# DA1470x register map
Vendor: Dialog; Series: DA1470x; File version: 1.2
CPU: CM33 r0p2, little endian, MPU, FPU, DSP, VTOR, 4 interrupt priority bits
Registers are 32-bit, read-write, reset 0x0 unless marked. A register's access mark holds for its fields unless they carry their own. Offsets are from the block's base; [hi:lo] are bit positions.

## EMMC (part 1 of 3) — EMMC registers
Base 0x30058000
0x00 EMMC_SDMASA_R_REG (reset mask 0x7FFFFFFF) — This register is used to configure a 32-bit Block Count or an SDMA System Address based on the Host Version 4 Enable bit in the
  [31:0] BLOCKCNT_SDMASA — 32-bit Block Count (SDMA System Address). - SDMA System Address (Host Version 4 Enable = 0): This register contains the system memory address for an SDMA transfer in the 32-bit addressing mode. When the Host Controller stops an SDMA transfer, this register points to the system address of the next contiguous data position. It can be accessed only if no transaction is executing. Reading this register during data transfers may return an invalid value. - 32-bit Block Count (Host Version 4 Enable = 1): From the Host Controller Version 4.10 specification, this register is redefined as 32-bit Block Count. The Host Controller decrements the block count of this register for every block transfer and the data transfer stops when the count reaches zero. This register must be accessed when no transaction is executing. Reading this register during data transfers may return invalid value. Following are the values for BLOCKCNT_SDMASA: - 0xFFFF_FFFF: 4G - 1 Block - ... - 0x0000_0002: 2 Blocks - 0x0000_0001: 1 Block - 0x0000_0000: Stop Count Note: - For Host Version 4 Enable = 0, the Host driver does not program the system address in this register while operating in ADMA mode. The system address must be programmed in the ADMA System Address register. - For Host Version 4 Enable = 0, the Host driver programs a non-zero 32-bit block count value in this register when Auto CMD23 is enabled for non-DMA and ADMA modes. Auto CMD23 cannot be used with SDMA. - This register must be programmed with a non-zero value for data transfer if the 32-bit Block count register is used instead of the 16-bit Block count register.
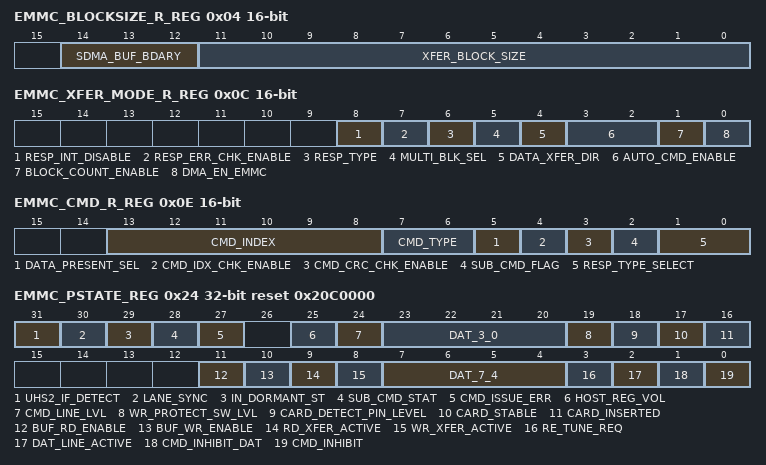
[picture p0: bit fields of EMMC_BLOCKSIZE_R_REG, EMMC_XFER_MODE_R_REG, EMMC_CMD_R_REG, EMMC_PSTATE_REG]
0x04 EMMC_BLOCKSIZE_R_REG 16-bit — This register is used to configure an SDMA buffer boundary and the number of bytes in a data block. This register is applicable
  [14:12] SDMA_BUF_BDARY — SDMA Buffer Boundary. These bits specify the size of contiguous buffer in system memory. The SDMA transfer waits at every boundary specified by these fields and the Host Controller generates the DMA interrupt to request the Host Driver to update the SDMA System Address register. Values: 0x0 (BYTES_4K): 4K bytes SDMA Buffer Boundary 0x1 (BYTES_8K): 8K bytes SDMA Buffer Boundary 0x2 (BYTES_16K): 16K bytes SDMA Buffer Boundary 0x3 (BYTES_32K): 32K bytes SDMA Buffer Boundary 0x4 (BYTES_64K): 64K bytes SDMA Buffer Boundary 0x5 (BYTES_128K): 128K bytes SDMA Buffer Boundary 0x6 (BYTES_256K): 256K bytes SDMA Buffer Boundary 0x7 (BYTES_512K): 512K bytes SDMA Buffer Boundary
  [11:0] XFER_BLOCK_SIZE — Transfer Block Size. These bits specify the block size of data transfers. In case of memory, it is set to 512 bytes. It can be accessed only if no transaction is executing. Read operations during transfers may return an invalid value, and write operations are ignored. Following are the values for XFER_BLOCK_SIZE: - 0x1: 1 byte - 0x2: 2 bytes - 0x3: 3 bytes - ...... - 0x1FF: 511 byte - 0x200: 512 bytes - ...... - 0x800: 2048 bytes Note: This register must be programmed with a non-zero value for data transfer.
0x06 EMMC_BLOCKCOUNT_R_REG 16-bit — This register is used to configure the number of data blocks. This register is applicable for both SD and eMMC modes.
  [15:0] BLOCK_CNT — 16-bit Block Count. - If the Host Version 4 Enable bit is set 0 or the 16-bit Block Count register is set to non-zero, the 16-bit Block Count register is selected. - If the Host Version 4 Enable bit is set 1 and the 16-bit Block Count register is set to zero, the 32-bit Block Count register is selected. Following are the values for BLOCK_CNT: - 0x0: Stop Count - 0x1: 1 Block - 0x2: 2 Blocks - ... - ... - 0xFFFF: 65535 Blocks Note: For Host Version 4 Enable = 0, this register must be set to 0000h before programming the 32-bit block count register when Auto CMD23 is enabled for non-DMA and ADMA modes.
0x08 EMMC_ARGUMENT_R_REG (reset mask 0x7FFFFFFF) — This register is used to configure the SD/eMMC command argument.
  [31:0] ARGUMENT — Command Argument. These bits specify the SD/eMMC command argument that is specified in bits 39-8 of the Command format.
0x0C EMMC_XFER_MODE_R_REG 16-bit — This register is used to control the operation of data transfers for an SD/eMMC mode. The Host driver sets this register before
  [8] RESP_INT_DISABLE — Response Interrupt Disable. The Host Controller supports response check function to avoid overhead of response error check by the Host driver. Response types of only R1 and R5 can be checked by the Controller. If Host Driver checks the response error, set this bit to 0 and wait for Command Complete Interrupt and then check the response register. If the Host Controller checks the response error, set this bit to 1 and set the Response Error Check Enable bit to 1. The Command Complete Interrupt is disabled by this bit regardless of the Command Complete Signal Enable. Note: During tuning (when the Execute Tuning bit in the Host Control2 register is set), the Command Complete Interrupt is not generated irrespective of the Response Interrupt Disable setting. Values: 0x0 (ENABLED): Response Interrupt is enabled 0x1 (DISABLED): Response Interrupt is disabled
  [7] RESP_ERR_CHK_ENABLE — Response Error Check Enable. The Host Controller supports response check function to avoid overhead of response error check by Host driver. Response types of only R1 and R5 can be checked by the Controller. If the Host Controller checks the response error, set this bit to 1 and set Response Interrupt Disable to 1. If an error is detected, the Response Error interrupt is generated in the Error Interrupt Status register. Note: - Response error check must not be enabled for any response type other than R1 and R5. - Response check must not be enabled for the tuning command. Values: 0x0 (DISABLED): Response Error Check is disabled 0x1 (ENABLED): Response Error Check is enabled
  [6] RESP_TYPE — Response Type R1/R5. This bit selects either R1 or R5 as a response type when the Response Error Check is selected. Error statuses checked in R1: - OUT_OF_RANGE - ADDRESS_ERROR - BLOCK_LEN_ERROR - WP_VIOLATION - CARD_IS_LOCKED - COM_CRC_ERROR - CARD_ECC_FAILED - CC_ERROR - ERROR Response Flags checked in R5: - COM_CRC_ERROR - ERROR - FUNCTION_NUMBER - OUT_OF_RANGE Values: 0x0 (RESP_R1): R1 (Memory) 0x1 (RESP_R5): R5 (SDIO)
  [5] MULTI_BLK_SEL — Multi/Single Block Select. This bit is set when issuing multiple-block transfer commands using the DAT line. If this bit is set to 0, it is not necessary to set the Block Count register. Values: 0x0 (SINGLE): Single Block 0x1 (MULTI): Multiple Block
  [4] DATA_XFER_DIR — Data Transfer Direction Select. This bit defines the direction of DAT line data transfers. This bit is set to 1 by the Host Driver to transfer data from the SD/eMMC card to the Host Controller and it is set to 0 for all other commands. Values: 0x1 (READ): Read (Card to Host) 0x0 (WRITE): Write (Host to Card)
  [3:2] AUTO_CMD_ENABLE — Auto Command Enable. This field determines use of Auto Command functions. Note: In SDIO, this field must be set as 00b (Auto Command Disabled). Values: 0x0 (AUTO_CMD_DISABLED): Auto Command Disabled 0x1 (AUTO_CMD12_ENABLED): Auto CMD12 Enable 0x2 (AUTO_CMD23_ENABLED): Auto CMD23 Enable 0x3 (AUTO_CMD_AUTO_SEL): Auto CMD Auto Select
  [1] BLOCK_COUNT_ENABLE — Block Count Enable. This bit is used to enable the Block Count register, which is relevant for multiple block transfers. If this bit is set to 0, the Block Count register is disabled, which is useful in executing an infinite transfer. The Host Driver must set this bit to 0 when ADMA is used. Values: 0x1 (ENABLED): Enable 0x0 (DISABLED): Disable
  [0] DMA_EN_EMMC — DMA Enable. This bit enables the DMA functionality. If this bit is set to 1, a DMA operation begins when the Host Driver writes to the Command register. You can select one of the DMA modes by using DMA Select in the Host Control 1 register. Values: 0x1 (ENABLED): DMA Data transfer 0x0 (DISABLED): No data transfer or Non-DMA data transfer
0x0E EMMC_CMD_R_REG 16-bit — This register is used to provide the information related to a command and a response packet. This register is applicable for an
  [13:8] CMD_INDEX — Command Index. These bits are set to the command number that is specified in bits 45-40 of the Command Format.
  [7:6] CMD_TYPE — Command Type. These bits indicate the command type. Note: While issuing Abort CMD using CMD12/CMD52 or reset CMD using CMD0/CMD52, CMD_TYPE field shall be set to 0x3. Values: 0x3 (ABORT_CMD): Abort 0x2 (RESUME_CMD): Resume 0x1 (SUSPEND_CMD): Suspend 0x0 (NORMAL_CMD): Normal
  [5] DATA_PRESENT_SEL — Data Present Select. This bit is set to 1 to indicate that data is present and that the data is transferred using the DAT line. This bit is set to 0 in the following instances: - Command using the CMD line - Command with no data transfer but using busy signal on the DAT[0] line - Resume Command Values: 0x0 (NO_DATA): No Data Present 0x1 (DATA): Data Present
  [4] CMD_IDX_CHK_ENABLE — Command Index Check Enable. This bit enables the Host Controller to check the index field in the response to verify if it has the same value as the command index. If the value is not the same, it is reported as a Command Index error. Note: - Index Check enable must be set to 0 for the command with no response, R2 response, R3 response and R4 response. - For the tuning command, this bit must always be set to enable the index check. Values: 0x0 (DISABLED): Disable 0x1 (ENABLED): Enable
  [3] CMD_CRC_CHK_ENABLE — Command CRC Check Enable. This bit enables the Host Controller to check the CRC field in the response. If an error is detected, it is reported as a Command CRC error. Note: - CRC Check enable must be set to 0 for the command with no response, R3 response, and R4 response. - For the tuning command, this bit must always be set to 1 to enable the CRC check. Values: 0x0 (DISABLED): Disable 0x1 (ENABLED): Enable
  [2] SUB_CMD_FLAG — Sub Command Flag. This bit distinguishes between a main command and a sub command. Values: 0x0 (MAIN): Main Command 0x1 (SUB): Sub Command
  [1:0] RESP_TYPE_SELECT — Response Type Select. This bit indicates the type of response expected from the card. Values: 0x0 (NO_RESP): No Response 0x1 (RESP_LEN_136): Response Length 136 0x2 (RESP_LEN_48): Response Length 48 0x3 (RESP_LEN_48B): Response Length 48; Check Busy after response
0x10 EMMC_RESP01_R_REG (reset mask 0x7FFFFFFF) — This register stores 39-08 bits of the Response Field for an SD/eMMC mode. The response for an SD/eMMC command can be a maximu
  [31:0] RESP01 ro — Command Response. These bits reflect 39-8 bits of SD/eMMC Response Field. Note: For Auto CMD, the 32-bit response (bits 39-8 of the Response Field) is updated in the RESP67_R register.
0x14 EMMC_RESP23_R_REG (reset mask 0x7FFFFFFF) — This register stores 71-40 bits of the Response Field for an SD/eMMC mode. This register is used to store the response from the
  [31:0] RESP23 ro — Command Response. These bits reflect 71-40 bits of the SD/eMMC Response Field.
0x18 EMMC_RESP45_R_REG (reset mask 0x7FFFFFFF) — This register stores 103-72 bits of the Response Field for an SD/eMMC mode. The response for SD/eMMC command can be a maximum
  [31:0] RESP45 ro — Command Response. These bits reflect 103-72 bits of the Response Field.
0x1C EMMC_RESP67_R_REG (reset mask 0x7FFFFFFF) — This register stores 135-104 bits of the Response Field for an SD/eMMC mode. The SD/eMMC response can be a maximum of 128 bi
  [31:0] RESP67 ro — Command Response. These bits reflect bits 135-104 of SD/EMMC Response Field. Note: For Auto CMD, this register also reflects the 32-bit response (bits 39-8 of the Response Field).
0x20 EMMC_BUF_DATA_R_REG (reset mask 0x7FFFFFFF) — This register is used to access the packet buffer. This register is applicable for an SD/eMMC/UHS-II mode.
  [31:0] BUF_DATA — Buffer Data. These bits enable access to the Host Controller packet buffer.
0x24 EMMC_PSTATE_REG reset 0x20C0000 (reset mask 0x7FFFFFFF) — This register indicates the present status of the Host Controller. This register is applicable for an SD/eMMC/UHS-II mode.
  [31] UHS2_IF_DETECT ro — UHS-II Interface Detection. For SD/eMMC mode, this bit always returns 0. Values: 0x0 (FALSE): UHS-II interface is not detected 0x1 (TRUE): UHS-II interface is detected
  [30] LANE_SYNC ro — Lane Synchronization. For SD/eMMC mode, this bit always returns 0. Values: 0x0 (FALSE): UHS-II PHY is not initialized 0x1 (TRUE): UHS-II PHY is initialized
  [29] IN_DORMANT_ST ro — In Dormant Status For SD/eMMC mode, this bit always returns 0. Values: 0x0 (FALSE): Not in DORMANT state 0x1 (TRUE): In DORMANT state
  [28] SUB_CMD_STAT ro — Sub Command Status. This bit is used to distinguish between a main command and a sub command status. Values: 0x0 (FALSE): Main Command Status 0x1 (TRUE): Sub Command Status
  [27] CMD_ISSUE_ERR ro — Command Not Issued by Error. This bit is set if a command cannot be issued after setting the command register due to an error except the Auto CMD12 error. Values: 0x0 (FALSE): No error for issuing a command 0x1 (TRUE): Command cannot be issued
  [25] HOST_REG_VOL ro — Host Regulator Voltage Stable. This bit is used to check whether the host regulator voltage is stable for switching the voltage of UHS-I mode. This bit reflects the synchronized value of the host_reg_vol_stable signal. Values: Description 0x0 (FALSE): Host Regulator Voltage is not stable 0x1 (TRUE): Host Regulator Voltage is stable
  [24] CMD_LINE_LVL ro — Command-Line Signal Level. This bit is used to check the CMD line level to recover from errors and for debugging. These bits reflect the value of the sd_cmd_in signal.
  [23:20] DAT_3_0 ro — DAT[3:0] Line Signal Level. This bit is used to check the DAT line level to recover from errors and for debugging. These bits reflect the value of the sd_dat_in (lower nibble) signal.
  [19] WR_PROTECT_SW_LVL ro — Write Protect Switch Pin Level. This bit is supported only for memory and combo cards. This bit reflects the synchronized value of the card_write_prot signal. Values: 0x0 (FALSE): Write protected 0x1 (TRUE): Write enabled
  [18] CARD_DETECT_PIN_LEVEL ro — Card Detect Pin Level. This bit reflects the inverse synchronized value of the card_detect_n signal. Values: 0x0 (FALSE): No card present 0x1 (TRUE): Card Present
  [17] CARD_STABLE ro — Card Stable. This bit indicates the stability of the Card Detect Pin Level. A card is not detected if this bit is set to 1 and the value of the CARD_INSERTED bit is 0. Values: 0x0 (FALSE): Reset or Debouncing 0x1 (TRUE): No Card or Inserted
  [16] CARD_INSERTED ro — Card Inserted. This bit indicates whether a card has been inserted. The Host Controller debounces this signal so that Host Driver need not wait for it to stabilize. Values: 0x0 (FALSE): Reset, Debouncing, or No card 0x1 (TRUE): Card Inserted
  [11] BUF_RD_ENABLE ro — Buffer Read Enable. This bit is used for non-DMA transfers. This bit is set if valid data exists in the Host buffer. Values: 0x0 (DISABLED): Read disable 0x1 (ENABLED): Read enable
  [10] BUF_WR_ENABLE ro — Buffer Write Enable. This bit is used for non-DMA transfers. This bit is set if space is available for writing data. Values: 0x0 (DISABLED): Write disable 0x1 (ENABLED): Write enable
  [9] RD_XFER_ACTIVE ro — Read Transfer Active. This bit indicates whether a read transfer is active for SD/eMMC mode. Values: 0x0 (INACTIVE): No valid data 0x1 (ACTIVE): Transferring data
  [8] WR_XFER_ACTIVE ro — Write Transfer Active. This status indicates whether a write transfer is active for SD/eMMC mode. Values: 0x0 (INACTIVE): No valid data 0x1 (ACTIVE): Transferring data
  [7:4] DAT_7_4 ro — DAT[7:4] Line Signal Level. This bit is used to check the DAT line level to recover from errors and for debugging. These bits reflect the value of the sd_dat_in (upper nibble) signal.
  [3] RE_TUNE_REQ ro — Re-Tuning Request. DWC_mshc does not generate retuning request. The software must maintain the Retuning timer.
  [2] DAT_LINE_ACTIVE ro — DAT Line Active (SD/eMMC Mode only). This bit indicates whether one of the DAT lines on the SD/eMMC bus is in use. In the case of read transactions, this bit indicates whether a read transfer is executing on the SD/eMMC bus. In the case of write transactions, this bit indicates whether a write transfer is executing on the SD/eMMC bus. For a command with busy, this status indicates whether the command executing busy is executing on an SD or eMMC bus. Values: 0x0 (INACTIVE): DAT Line Inactive 0x1 (ACTIVE): DAT Line Active
  [1] CMD_INHIBIT_DAT ro — Command Inhibit (DAT). This bit is applicable for SD/eMMC mode and is generated if either DAT line active or Read transfer active is set to 1. If this bit is set to 0, it indicates that the Host Controller can issue subsequent SD/eMMC commands. Values: 0x0 (READY): Can issue command which used DAT line 0x1 (NOT_READY): Cannot issue command which used DAT line
  [0] CMD_INHIBIT ro — Command Inhibit (CMD). This bit indicates the following : - SD/eMMC mode: If this bit is set to 0, it indicates that the CMD line is not in use and the Host controller can issue an SD/eMMC command using the CMD line. This bit is set when the command register is written. This bit is cleared when the command response is received. This bit is not cleared by the response of auto CMD12/23 but cleared by the response of read/write command. Values: 0x0 (READY): Host Controller is ready to issue a command 0x1 (NOT_READY): Host Controller is not ready to issue a command
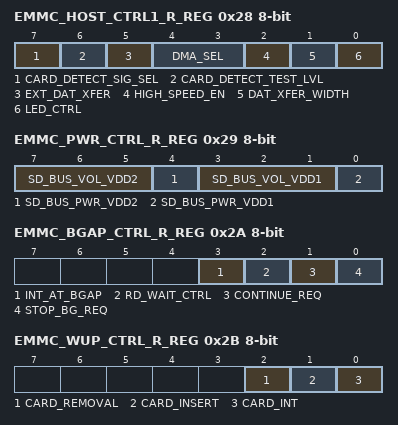
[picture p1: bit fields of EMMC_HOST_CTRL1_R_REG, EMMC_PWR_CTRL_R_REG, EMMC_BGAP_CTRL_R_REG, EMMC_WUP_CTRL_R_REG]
0x28 EMMC_HOST_CTRL1_R_REG 8-bit — This register is used to control the operation of the Host Controller. This register is applicable for an SD/eMMC/UHS-II mode.
  [7] CARD_DETECT_SIG_SEL — Card Detect Signal Selection. This bit selects a source for card detection. When the source for the card detection is switched, the interrupt must be disabled during the switching period. Values: 0x1 (CARD_DT_TEST_LEVEL): Card Detect Test Level is selected (for test purpose) 0x0 (SDCD_PIN): SDCD# (card_detect_n signal) is selected (for normal use)
  [6] CARD_DETECT_TEST_LVL — Card Detect Test Level. This bit is enabled while the Card Detect Signal Selection is set to 1 and it indicates whether a card inserted or not. Values: 0x1 (CARD_INSERTED): Card Inserted 0x0 (No_CARD): No Card
  [5] EXT_DAT_XFER — Extended Data Transfer Width. This bit controls 8-bit bus width mode of embedded device. Values: 0x1 (EIGHT_BIT): 8-bit Bus Width 0x0 (DEFAULT): Bus Width is selected by the Data Transfer Width
  [4:3] DMA_SEL — DMA Select. This field is used to select the DMA type. When Host Version 4 Enable is 1 in Host Control 2 register: - 0x0 : SDMA is selected - 0x1 : Reserved - 0x2 : ADMA2 is selected - 0x3 : ADMA2 or ADMA3 is selected When Host Version 4 Enable is 0 in Host Control 2 register: - 0x0 : SDMA is selected - 0x1 : Reserved - 0x2 : 32-bit Address ADMA2 is selected - 0x3 : 64-bit Address ADMA2 is selected Values: 0x0 (SDMA): SDMA is selected 0x1 (RSVD_BIT): Reserved 0x2 (ADMA2): ADMA2 is selected 0x3 (ADMA2_3): ADMA2 or ADMA3 is selected
  [2] HIGH_SPEED_EN — High Speed Enable (SD/eMMC Mode only). In SD/eMMC mode, this bit is used to determine the selection of preset value for High Speed mode. Before setting this bit, the Host Driver checks the High Speed Support in the Capabilities register. Note: DWC_MSHC always outputs the sd_cmd_out and sd_dat_out lines at the rising edge of cclk_tx clock irrespective of this bit.Please refer the section Connecting the Clock IO interface in the Mobile Storage Host Controller user guide on clocking requirement for an SD/eMMC card. Values: 0x1 (HIGH_SPEED): High Speed mode 0x0 (NORMAL_SPEED): Normal Speed mode
  [1] DAT_XFER_WIDTH — Data Transfer Width. For SD/eMMC mode,this bit selects the data transfer width of the Host Controller. The Host Driver sets it to match the data width of the SD/eMMC card. Values: 0x1 (FOUR_BIT): 4-bit mode 0x0 (ONE_BIT): 1-bit mode
  [0] LED_CTRL — LED Control. This bit is used to caution the user not to remove the card while the SD card is being accessed. The value is reflected on the led_control signal. Values: 0x0 (OFF): LED off 0x1 (ON): LED on
0x29 EMMC_PWR_CTRL_R_REG 8-bit — This register is used to control the bus power for the Card. This register is applicable for an SD, eMMC, and UHS-II modes.
  [7:5] SD_BUS_VOL_VDD2 — SD Bus Voltage Select for VDD2. This is irrelevant for SD/eMMC card. Values: 0x7 (NOT_USED7): Not used 0x6 (NOT_USED6): Not used 0x5 (V_1_8): 1.8V 0x4 (V_1_2): Reserved for 1.2V 0x3 (RSVD3): Reserved 0x2 (RSVD2): Reserved 0x1 (RSVD1): Reserved 0x0 (NO_VDD2): VDD2 Not Supported
  [4] SD_BUS_PWR_VDD2 — SD Bus Power for VDD2. This is irrelevant for SD/eMMC card. Values: 0x0 (OFF): Power off 0x1 (ON): Power on
  [3:1] SD_BUS_VOL_VDD1 — SD Bus Voltage Select for VDD1/eMMC Bus Voltage Select for VDD. These bits enable the Host Driver to select the voltage level for an SD/eMMC card. Before setting this register, the Host Driver checks the Voltage Support bits in the Capabilities register. If an unsupported voltage is selected, the Host System does not supply the SD Bus voltage. The value set in this field is available on the DWC_mshc output signal (sd_vdd1_sel), which is used by the voltage switching circuitry. SD Bus Voltage Select options: - 0x7 : 3.3V(Typical) - 0x6 : 3.0V(Typical) - 0x5 : 1.8V(Typical) for Embedded - 0x4 : 0x0 - Reserved eMMC Bus Voltage Select options: - 0x7 : 3.3V(Typical) - 0x6 : 1.8V(Typical) - 0x5 : 1.2V(Typical) - 0x4 : 0x0 - Reserved Values: 0x7 (V_3_3): 3.3V (Typ.) 0x6 (V_3_0): 3.0V (Typ.) 0x5 (V_1_8): 1.8V (Typ.) for Embedded 0x4 (RSVD4): Reserved 0x3 (RSVD3): Reserved 0x2 (RSVD2): Reserved 0x1 (RSVD1): Reserved 0x0 (RSVD0): Reserved
  [0] SD_BUS_PWR_VDD1 — SD Bus Power for VDD1. This bit enables VDD1 power of the card. This setting is available on the sd_vdd1_on output of DWC_mshc so that it can be used to control the VDD1 power supply of the card. Before setting this bit, the SD Host Driver sets the SD Bus Voltage Select bit. If the Host Controller detects a No Card state, this bit is cleared. In SD mode, if this bit is cleared, the Host Controller stops the SD Clock by clearing the SD_CLK_IN bit in the CLK_CTRL_R register. Values: 0x0 (OFF): Power off 0x1 (ON): Power on
0x2A EMMC_BGAP_CTRL_R_REG 8-bit — This register is used by the host driver to control any operation related to Block Gap. This register is applicable for an SD/e
  [3] INT_AT_BGAP — Interrupt At Block Gap. This bit is valid only in the 4-bit mode of an SDIO card and is used to select a sample point in the interrupt cycle. Setting to 1 enables interrupt detection at the block gap for a multiple block transfer. Values: 0x0 (DISABLE): Disabled 0x1 (ENABLE): Enabled
  [2] RD_WAIT_CTRL — Read Wait Control. This bit is used to enable the read wait protocol to stop read data using DAT[2] line if the card supports read wait. Otherwise, the Host Controller has to stop the card clock to hold the read data. Values: 0x0 (DISABLE): Disable Read Wait Control 0x1 (ENABLE): Enable Read Wait Control
  [1] CONTINUE_REQ — Continue Request. This bit is used to restart the transaction, which was stopped using the Stop At Block Gap Request. The Host Controller automatically clears this bit when the transaction restarts. If stop at block gap request is set to 1, any write to this bit is ignored. Values: 0x0 (NO_AFFECT): No Affect 0x1 (RESTART): Restart
  [0] STOP_BG_REQ — Stop At Block Gap Request. This bit is used to stop executing read and write transactions at the next block gap for non-DMA, SDMA, and ADMA transfers. Values: 0x0 (XFER): Transfer 0x1 (STOP): Stop
0x2B EMMC_WUP_CTRL_R_REG 8-bit — This register is mandatory for the Host Controller, but the wakeup functionality depends on the Host Controller system hardware
  [2] CARD_REMOVAL — Wakeup Event Enable on SD Card Removal. This bit enables wakeup event through Card Removal assertion in the Normal Interrupt Status register. For the SDIO card, Wake Up Support (FN_WUS) in the Card Information Structure (CIS) register does not affect this bit. Values: 0x0 (DISABLED): Disable 0x1 (ENABLED): Enable
  [1] CARD_INSERT — Wakeup Event Enable on SD Card Insertion. This bit enables wakeup event through Card Insertion assertion in the Normal Interrupt Status register. FN_WUS (Wake Up Support) in CIS does not affect this bit. Values: 0x0 (DISABLED): Disable 0x1 (ENABLED): Enable
  [0] CARD_INT — Wakeup Event Enable on Card Interrupt. This bit enables wakeup event through a Card Interrupt assertion in the Normal Interrupt Status register. This bit can be set to 1 if FN_WUS (Wake Up Support) in CIS is set to 1. Values: 0x0 (DISABLED): Disable 0x1 (ENABLED): Enable
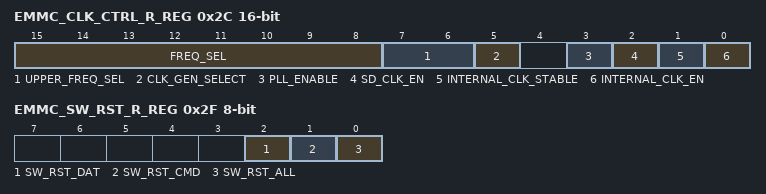
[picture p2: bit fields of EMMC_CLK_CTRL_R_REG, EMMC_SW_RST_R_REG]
0x2C EMMC_CLK_CTRL_R_REG 16-bit — This register controls SDCLK (card clock) in an SD/eMMC mode and RCLK in the UHS-II mode. This register is applicable for an SD
  [15:8] FREQ_SEL — SDCLK/RCLK Frequency Select. These bits are used to select the frequency of the SDCLK signal. These bits depend on setting of Preset Value Enable in the Host Control 2 register. If Preset Value Enable = 0, these bits are set by the Host Driver. If Preset Value Enable = 1, these bits are automatically set to a value specified in one of the Preset Value register. The value is reflected on the lower 8-bit of the card_clk_freq_sel signal. 10-bit Divided Clock Mode: - 0x3FF : 1/2046 Divided clock - N : 1/2N Divided Clock - 0x002 : 1/4 Divided Clock - 0x001 : 1/2 Divided Clock - 0x000 : Base clock (10MHz - 255 MHz) Programmable Clock Mode : Enables the Host System to select a fine grain SD clock frequency: - 0x3FF : Base clock * M /1024 - N-1 : Base clock * M /N - 0x002 : Base clock * M /3 - 0x001 : Base clock * M /2 - 0x000 : Base clock * M
  [7:6] UPPER_FREQ_SEL — These bits specify the upper 2 bits of 10-bit SDCLK/RCLK Frequency Select control. The value is reflected on the upper 2 bits of the card_clk_freq_sel signal.
  [5] CLK_GEN_SELECT — Clock Generator Select. This bit is used to select the clock generator mode in SDCLK/RCLK Frequency Select. If Preset Value Enable = 0, this bit is set by the Host Driver. If Preset Value Enable = 1, this bit is automatically set to a value specified in one of the Preset Value registers. The value is reflected on the card_clk_gen_sel signal. Values: 0x0 (FALSE): Divided Clock Mode 0x1 (TRUE): Programmable Clock Mode
  [3] PLL_ENABLE — PLL Enable. This bit is used to activate the PLL (applicable when Host Version 4 Enable = 1). When Host Version 4 Enable = 0, INTERNAL_CLK_EN bit may be used to activate PLL. The value is reflected on the card_clk_en signal. Note: If this bit is not used to to active the PLL when Host Version 4 Enable = 1, it is recommended to set this bit to '1' . Values: 0x0 (FALSE): PLL is in low power mode 0x1 (TRUE): PLL is enabled
  [2] SD_CLK_EN — SD/eMMC Clock Enable. This bit stops the SDCLK or RCLK when set to 0. The SDCLK/RCLK Frequency Select bit can be changed when this bit is set to 0. The value is reflected on the clk2card_on pin. Values: 0x0 (FALSE): Disable providing SDCLK/RCLK 0x1 (TRUE): Enable providing SDCLK/RCLK
  [1] INTERNAL_CLK_STABLE ro — Internal Clock Stable This bit enables the Host Driver to check the clock stability twice after the Internal Clock Enable bit is set and after the PLL Enable bit is set. This bit reflects the synchronized value of the intclk_stable signal after the Internal Clock Enable bit is set to 1 and also reflects the synchronized value of the card_clk_stable signal after the PLL Enable bit is set to 1. Values: 0x0 (FALSE): Not Ready 0x1 (TRUE): Ready
  [0] INTERNAL_CLK_EN — Internal Clock Enable. This bit is set to 0 when the Host Driver is not using the Host Controller or the Host Controller awaits a wakeup interrupt. The Host Controller must stop its internal clock to enter a very low power state. However, registers can still be read and written to. The value is reflected on the intclk_en signal. Note: If this bit is not used to control the internal clock (base clock and master clock), it is recommended to set this bit to '1'. Values: 0x0 (FALSE): Stop 0x1 (TRUE): Oscillate
0x2E EMMC_TOUT_CTRL_R_REG 8-bit — This register is used to set the Data Timeout Counter value for an SD/eMMC mode according to the timer clock defined by the Cap
  [3:0] TOUT_CNT — Data Timeout Counter Value. This value determines the interval by which DAT line timeouts are detected. The Timeout clock frequency is generated by dividing the base clock TMCLK value by this value. When setting this register, prevent inadvertent timeout events by clearing the Data Timeout Error Status Enable (in the Error Interrupt Status Enable register). The values for these bits are: - 0xF : Reserved - 0xE : TMCLK x 2^27 - 0x1 : TMCLK x 2^14 - 0x0 : TMCLK x 2^13 Note: During a boot operating in an eMMC mode, an application must configure the boot data timeout value (approximately 1 sec) in this bit.
0x2F EMMC_SW_RST_R_REG 8-bit — This register is used to generate a reset pulse by writing 1 to each bit of this register. After completing the reset, the Host
  [2] SW_RST_DAT — Software Reset For DAT line. This bit is used in SD/eMMC mode and it resets only a part of the data circuit and the DMA circuit is also reset. The following registers and bits are cleared by this bit: - Buffer Data Port register -- Buffer is cleared and initialized. - Present state register -- Buffer Read Enable -- Buffer Write Enable -- Read Transfer Active -- Write Transfer Active -- DAT Line Active -- Command Inhibit (DAT) - Block Gap Control register -- Continue Request -- Stop At Block Gap Request - Normal Interrupt status register -- Buffer Read Ready -- Buffer Write Ready -- DMA Interrupt -- Block Gap Event -- Transfer Complete Values: 0x0 (FALSE): Work 0x1 (TRUE): Reset
  [1] SW_RST_CMD — Software Reset For CMD line. This bit resets only a part of the command circuit to be able to issue a command. This reset is effective only for a command issuing circuit (including response error statuses related to Command Inhibit (CMD) control) and does not affect the data transfer circuit. Host Controller can continue data transfer even after this reset is executed while handling subcommand-response errors. The following registers and bits are cleared by this bit: - Present State register : Command Inhibit (CMD) bit - Normal Interrupt Status register : Command Complete bit - Error Interrupt Status : Response error statuses related to Command Inhibit (CMD) bit Values: 0x0 (FALSE): Work 0x1 (TRUE): Reset
  [0] SW_RST_ALL — Software Reset For All. This reset affects the entire Host Controller except for the card detection circuit. During its initialization, the Host Driver sets this bit to 1 to reset the Host Controller. All registers are reset except the capabilities register. If this bit is set to 1, the Host Driver must issue reset command and reinitialize the card. Values: 0x0 (FALSE): Work 0x1 (TRUE): Reset
